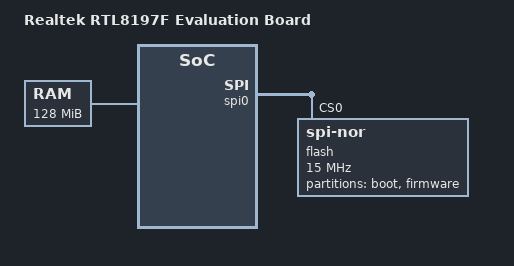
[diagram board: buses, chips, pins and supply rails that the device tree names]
// SPDX-License-Identifier: GPL-2.0-or-later OR MIT

#include <dt-bindings/gpio/gpio.h>
#include <dt-bindings/input/input.h>

#include "rtl8197f.dtsi"

/ {
	compatible = "realtek,rtl8197f-evb", "realtek,rtl8197f-vg", "realtek,rtl8197f-soc";
	model = "Realtek RTL8197F Evaluation Board";

	memory@0 {
		device_type = "memory";
		reg = <0x00000000 0x08000000>;
	};
};

&gpio0 {
	status = "okay";
};

&spi0 {
	status = "okay";

	flash@0 {
		compatible = "jedec,spi-nor";
		reg = <0>;
		spi-max-frequency = <15000000>;

		partitions {
			compatible = "fixed-partitions";
			#address-cells = <1>;
			#size-cells = <1>;

			partition@0 {
				label = "boot";
				reg = <0x00000000 0x000c0000>;
				read-only;
			};

			firmware: partition@c0000 {
				label = "firmware";
				compatible = "openwrt,uimage";
				reg = <0x000c0000 0x00f40000>;
			};
		};
	};
};
